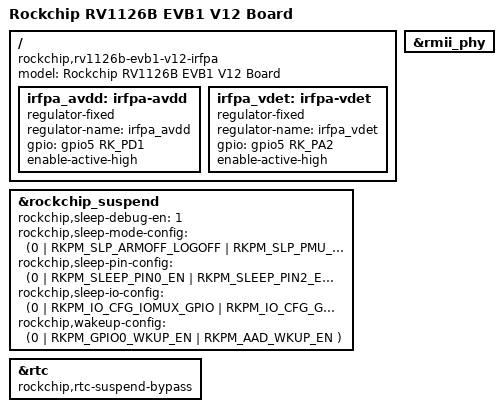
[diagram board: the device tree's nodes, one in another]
// SPDX-License-Identifier: (GPL-2.0+ OR MIT)
/*
 * Copyright (c) 2025 Rockchip Electronics Co., Ltd.
 */

/dts-v1/;
#include "rv1126b.dtsi"
#include "rv1126b-evb.dtsi"
#include "rv1126b-evb1-v12.dtsi"
#include "rv1126b-evb-cam-irfpa.dtsi"

/ {
	model = "Rockchip RV1126B EVB1 V12 Board";
	compatible = "rockchip,rv1126b-evb1-v12-irfpa", "rockchip,rv1126b";

	irfpa_avdd: irfpa-avdd {
		compatible = "regulator-fixed";
		regulator-name = "irfpa_avdd";
		gpio = <&gpio5 RK_PD1 GPIO_ACTIVE_HIGH>;
		enable-active-high;
	};

	irfpa_vdet: irfpa-vdet {
		compatible = "regulator-fixed";
		regulator-name = "irfpa_vdet";
		gpio = <&gpio5 RK_PA2 GPIO_ACTIVE_HIGH>;
		enable-active-high;
	};
};

/* Note: irfpa ooc pin confilt with fephym1_pins */
&rmii_phy {
	/delete-property/ pinctrl-0;
	/delete-property/ pinctrl-names;
};

&rockchip_suspend {
	status = "okay";

	rockchip,sleep-debug-en = <1>;

	rockchip,sleep-mode-config = <
		(0
		| RKPM_SLP_ARMOFF_LOGOFF
		| RKPM_SLP_PMU_PMUALIVE_32K
		| RKPM_SLP_PMU_DIS_OSC
		| RKPM_SLP_32K_EXT
		| RKPM_SLP_LP_AOA
		)
	>;

	rockchip,sleep-pin-config = <
		(0
		| RKPM_SLEEP_PIN0_EN
		| RKPM_SLEEP_PIN2_EN
		)
		(0
		| RKPM_SLEEP_PIN0_ACT_LOW
		)
	>;

	rockchip,sleep-io-config = <
		/* pmic_sleep */
		(0
		| RKPM_IO_CFG_IOMUX_GPIO
		| RKPM_IO_CFG_GPIO_DIR_INPUT
		| RKPM_IO_CFG_PULL_DOWN
		| RKPM_IO_CFG_ID(0)
		)
		/* reset */
		#if 0
		(0
		| RKPM_IO_CFG_IOMUX_GPIO
		| RKPM_IO_CFG_GPIO_DIR_INPUT
		| RKPM_IO_CFG_PULL_NONE
		| RKPM_IO_CFG_ID(1)
		)
		#endif
		(0
		| RKPM_IO_CFG_IOMUX_GPIO
		| RKPM_IO_CFG_GPIO_DIR_INPUT
		| RKPM_IO_CFG_PULL_DOWN
		| RKPM_IO_CFG_ID(2)
		)
		(0
		| RKPM_IO_CFG_PULL_NONE
		| RKPM_IO_CFG_ID(3)
		)
		(0
		| RKPM_IO_CFG_IOMUX_GPIO
		| RKPM_IO_CFG_GPIO_DIR_INPUT
		| RKPM_IO_CFG_PULL_DOWN
		| RKPM_IO_CFG_ID(4)
		)
		(0
		| RKPM_IO_CFG_IOMUX_GPIO
		| RKPM_IO_CFG_GPIO_DIR_INPUT
		| RKPM_IO_CFG_PULL_UP
		| RKPM_IO_CFG_ID(5)
		)
		(0
		| RKPM_IO_CFG_IOMUX_GPIO
		| RKPM_IO_CFG_GPIO_DIR_INPUT
		| RKPM_IO_CFG_PULL_DOWN
		| RKPM_IO_CFG_ID(6)
		)
		(0
		| RKPM_IO_CFG_IOMUX_GPIO
		| RKPM_IO_CFG_GPIO_DIR_INPUT
		| RKPM_IO_CFG_PULL_UP
		| RKPM_IO_CFG_ID(7)
		)
		(0
		| RKPM_IO_CFG_IOMUX_GPIO
		| RKPM_IO_CFG_GPIO_DIR_INPUT
		| RKPM_IO_CFG_PULL_DOWN
		| RKPM_IO_CFG_ID(8)
		)
		(0
		| RKPM_IO_CFG_IOMUX_GPIO
		| RKPM_IO_CFG_GPIO_DIR_INPUT
		| RKPM_IO_CFG_PULL_DOWN
		| RKPM_IO_CFG_ID(9)
		)
		(0
		| RKPM_IO_CFG_IOMUX_GPIO
		| RKPM_IO_CFG_GPIO_DIR_INPUT
		| RKPM_IO_CFG_PULL_DOWN
		| RKPM_IO_CFG_ID(10)
		)
		(0
		| RKPM_IO_CFG_IOMUX_GPIO
		| RKPM_IO_CFG_GPIO_DIR_INPUT
		| RKPM_IO_CFG_PULL_DOWN
		| RKPM_IO_CFG_ID(11)
		)
		(0
		| RKPM_IO_CFG_IOMUX_GPIO
		| RKPM_IO_CFG_GPIO_DIR_INPUT
		| RKPM_IO_CFG_PULL_DOWN
		| RKPM_IO_CFG_ID(12)
		)
		(0
		| RKPM_IO_CFG_IOMUX_GPIO
		| RKPM_IO_CFG_GPIO_DIR_INPUT
		| RKPM_IO_CFG_PULL_DOWN
		| RKPM_IO_CFG_ID(20)
		)
		(0
		| RKPM_IO_CFG_IOMUX_GPIO
		| RKPM_IO_CFG_GPIO_DIR_INPUT
		| RKPM_IO_CFG_PULL_DOWN
		| RKPM_IO_CFG_ID(21)
		)
		(0
		| RKPM_IO_CFG_IOMUX_GPIO
		| RKPM_IO_CFG_GPIO_DIR_INPUT
		| RKPM_IO_CFG_PULL_DOWN
		| RKPM_IO_CFG_ID(22)
		)
		(0
		| RKPM_IO_CFG_IOMUX_GPIO
		| RKPM_IO_CFG_GPIO_DIR_INPUT
		| RKPM_IO_CFG_PULL_DOWN
		| RKPM_IO_CFG_ID(23)
		)
		(0
		| RKPM_IO_CFG_IOMUX_GPIO
		| RKPM_IO_CFG_GPIO_DIR_INPUT
		| RKPM_IO_CFG_PULL_DOWN
		| RKPM_IO_CFG_ID(24)
		)
		(0
		| RKPM_IO_CFG_IOMUX_GPIO
		| RKPM_IO_CFG_GPIO_DIR_INPUT
		| RKPM_IO_CFG_PULL_DOWN
		| RKPM_IO_CFG_ID(25)
		)
	>;

	rockchip,wakeup-config = <
		(0
		| RKPM_GPIO0_WKUP_EN
		| RKPM_AAD_WKUP_EN
		)
	>;
};

&rtc {
	rockchip,rtc-suspend-bypass;
	status = "okay";
};
